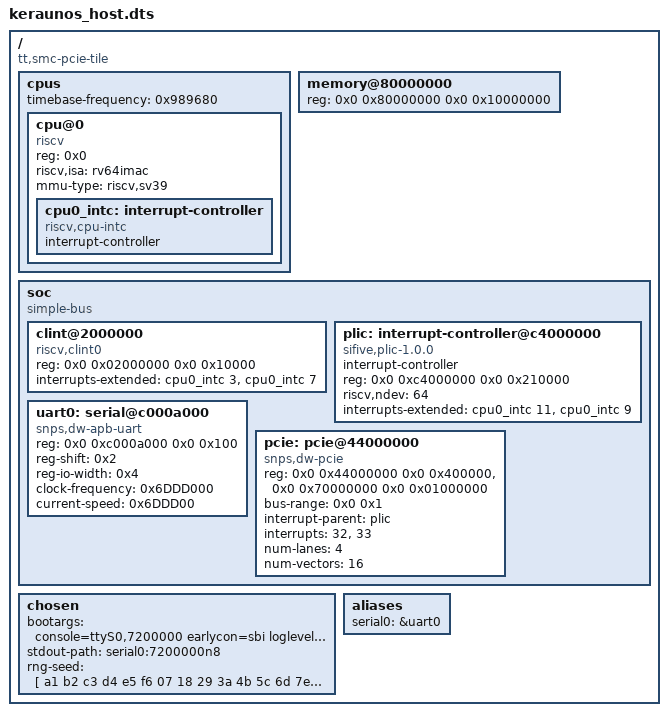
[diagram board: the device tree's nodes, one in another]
/dts-v1/;

/*
 * Device Tree for SMC_PCIE_Tile Host_Chiplet VDK.
 *
 * Addresses derived from Properties.xml iBus|TT_Rocket_LT_PSP_1_DATA
 * range_mappings and SharedMemoryMap_intf:
 *   DRAM:       0x80000000 (1 GB — bus maps 0x40000000 bytes)
 *   UART:       0xC000A000 (DW_APB_UART_SC)
 *   PLIC:       0xC4000000 (size 0x210000)
 *   CLINT:      0x02000000 (standard RISC-V, internal to Imperas)
 *   PCIe DBI:   0x44000000 (4 MB)
 *   PCIe ATU:   0x44300000 (128 KB)
 *   PCIe CFG:   0x70000000 (4 KB)
 */

/ {
    #address-cells = <0x2>;
    #size-cells = <0x2>;
    compatible = "tt,smc-pcie-tile";

    cpus {
        #address-cells = <0x1>;
        #size-cells = <0x0>;
        timebase-frequency = <0x989680>;    /* 10 MHz (was 100 MHz) — 10x fewer timer IRQs */

        cpu@0 {
            device_type = "cpu";
            reg = <0x0>;
            status = "okay";
            compatible = "riscv";
            riscv,isa = "rv64imac";
            mmu-type = "riscv,sv39";

            cpu0_intc: interrupt-controller {
                #interrupt-cells = <0x1>;
                interrupt-controller;
                compatible = "riscv,cpu-intc";
                phandle = <0x2>;
            };
        };
    };

    memory@80000000 {
        device_type = "memory";
        reg = <0x0 0x80000000 0x0 0x10000000>;
    };

    soc {
        #address-cells = <0x2>;
        #size-cells = <0x2>;
        compatible = "simple-bus";
        ranges;

        clint@2000000 {
            compatible = "riscv,clint0";
            reg = <0x0 0x02000000 0x0 0x10000>;
            interrupts-extended = <&cpu0_intc 3>, <&cpu0_intc 7>;
        };

        plic: interrupt-controller@c4000000 {
            compatible = "sifive,plic-1.0.0", "riscv,plic0";
            #interrupt-cells = <0x1>;
            interrupt-controller;
            reg = <0x0 0xc4000000 0x0 0x210000>;
            riscv,ndev = <64>;
            interrupts-extended = <&cpu0_intc 11>, <&cpu0_intc 9>;
            phandle = <0x1>;
        };

        uart0: serial@c000a000 {
            compatible = "snps,dw-apb-uart";
            reg = <0x0 0xc000a000 0x0 0x100>;
            reg-shift = <0x2>;
            reg-io-width = <0x4>;
            clock-frequency = <0x6DDD000>;   /* 115.2 MHz — matches vpcfg UART_CLK override */
            current-speed = <0x6DDD00>;    /* 7.2 Mbaud — divisor 1 for fastest polled I/O */
        };

        pcie: pcie@44000000 {
            compatible = "snps,dw-pcie";
            reg = <0x0 0x44000000 0x0 0x400000>,
                  <0x0 0x70000000 0x0 0x01000000>;
            reg-names = "dbi", "config";

            #address-cells = <3>;
            #size-cells = <2>;
            device_type = "pci";

            bus-range = <0x0 0x1>;

            /* Split AXI_Slave window (0x70000000, 256MB):
             * 0x70000000-0x70FFFFFF (16MB)  -> config region (CFG TLPs via iATU)
             * 0x71000000-0x7FFFFFFF (240MB) -> MEM region (MEM TLPs to EP BARs) */
            ranges =
                <0x02000000 0x0 0x71000000  0x0 0x71000000  0x0 0x0F000000>;

            interrupt-parent = <&plic>;
            /* Index 0 = MSI, Index 1 = INTx (pp->irq — mandatory for dw-pcie-plat probe) */
            interrupts = <32>, <33>;

            num-lanes = <4>;
            num-vectors = <16>;
            status = "okay";
        };
    };

    chosen {
        bootargs = "console=ttyS0,7200000 earlycon=sbi loglevel=4 ignore_loglevel nokaslr pci=noaer pcie_aspm=off";
        stdout-path = "serial0:7200000n8";
        /* 64 bytes of fixed seed so the CRNG is credited immediately at boot —
           eliminates the getrandom() stall in simulation (no HW entropy source). */
        rng-seed = [
            a1 b2 c3 d4 e5 f6 07 18  29 3a 4b 5c 6d 7e 8f 90
            01 12 23 34 45 56 67 78  89 9a ab bc cd de ef f0
            10 21 32 43 54 65 76 87  98 a9 ba cb dc ed fe 0f
            f1 e2 d3 c4 b5 a6 97 88  79 6a 5b 4c 3d 2e 1f 00
        ];
    };

    aliases {
        serial0 = &uart0;
    };
};
